AUTOSAR XML (schema 00047)
standard types defined: uint16, uint8
package /DemoApplication/ImplementationDataTypes
  impl type ComM_ModeType: compu {0=NO_COMMUNICATION, 1=SILENT_COMMUNICATION, 2=FULL_COMMUNICATION}, implementation-data-type=uint8
package /DemoApplication/PortInterfaces
  compu method DefaultBooleanCompuMethod: 0=false, 1=true
  sender receiver interface IfAdcVoltage
    data ArgData: type=uint16
  client server interface If_DiscreteValueOutput
    operation SetDiscreteValue
      arg value: type=uint32, direction=IN
  unit NoUnit
  client server interface NvMService0: is-service=true
    operation ReadBlock: fire-and-forget=false
      arg ReadArg: type=uint8, direction=IN, server-argument-impl-policy=USE-ARGUMENT-TYPE
    operation WriteBlock: fire-and-forget=false
      arg WriteArg: type=uint8, direction=IN, server-argument-impl-policy=USE-ARGUMENT-TYPE
    error E_NOT_OK: error-code=1
    error E_OK: error-code=0
package /DemoApplication/SwComponentTypes
  sw addr method LEDCODE: memory-allocation-keyword-policy=ADDR-METHOD-SHORT-NAME
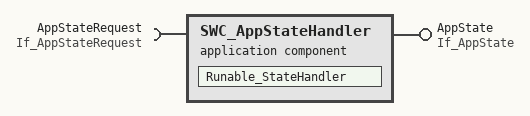
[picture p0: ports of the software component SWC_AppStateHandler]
  application sw component type SWC_AppStateHandler
    provide port AppState: mode-switch-sender-com-spec{mode-group=AppStateMode, queue-length=2}, provided-interface=If_AppState
    require port AppStateRequest: nonqueued-receiver-com-spec{data-element=If_AppStateRequestMode, init-value=EB_INTGR_APP_STARTUP}, required-interface=If_AppStateRequest
    behavior IB_SWC_AppStateHandler: data-type-mapping=AppModeMapping, handle-termination-and-restart=NO-SUPPORT
      data received event AppState: start-on-event=Runable_StateHandler, data=AppStateRequest.If_AppStateRequestMode
      runnable Runable_StateHandler: mode-access-point=AppState.AppStateMode, symbol=App_StateHandler
        data-read-access:
          access DRA_requestMode: accessed-variable=AppStateRequest.If_AppStateRequestMode
        mode switch point MSP_Mode: mode-group=AppState.AppStateMode
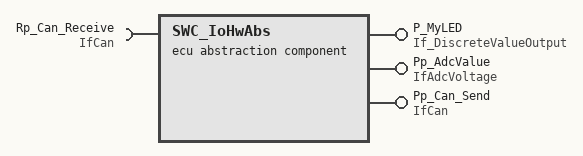
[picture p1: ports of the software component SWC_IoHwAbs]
  ecu abstraction sw component type SWC_IoHwAbs
    provide port P_MyLED: server-com-spec{operation=SetDiscreteValue, queue-length=1}, provided-interface=If_DiscreteValueOutput
    provide port Pp_AdcValue: nonqueued-sender-com-spec{data-element=ArgData, handle-out-of-range=DEFAULT, uses-end-to-end-protection=0, init-value=0}, provided-interface=IfAdcVoltage
    provide port Pp_Can_Send: nonqueued-sender-com-spec{data-element=Can, data-update-period=1.0, handle-out-of-range=DEFAULT, transmission-acknowledge=timeout=0.0, uses-end-to-end-protection=0}, provided-interface=IfCan
    require port Rp_Can_Receive: nonqueued-receiver-com-spec{data-element=Can, init-value=0}, required-interface=IfCan
    behavior IB_SWC_IoHwAbs: handle-termination-and-restart=NO-SUPPORT, port-api-option{enable-take-address=false, indirect-api=false, port-defined-argument-value{value=0, value-type=uint32}, port=P_MyLED}
      4 x timing event, all with offset=0.0:
        Adc_timingEvent: start-on-event=Adc_ReadValue, period=0.2
        LedTiming: start-on-event=LedControl_IO, period=0.2
        Recrive_Cyclic: start-on-event=Can_Receive, period=1.0
        Send_Cyclic: start-on-event=Can_Send, period=1.0
      operation invoked event SetDiscreteValueOperationInvoked: start-on-event=SetDiscreteValue, operation=P_MyLED.SetDiscreteValue
      5 x runnable:
        Adc_ReadValue
          data-send-points:
            access dsp_ArgData: accessed-variable=Pp_AdcValue.ArgData
        Can_Receive
          data-receive-point-by-values:
            access drpval_Can: accessed-variable=Rp_Can_Receive.Can
        Can_Send
          data-send-points:
            access dsp_Can: accessed-variable=Pp_Can_Send.Can
        LedControl_IO: can-be-invoked-concurrently=true
        SetDiscreteValue: can-be-invoked-concurrently=true, symbol=SWC_IoHwAbs_SetDiscreteValue
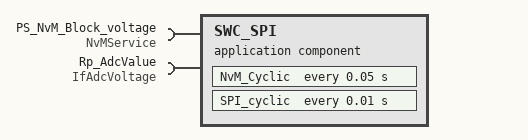
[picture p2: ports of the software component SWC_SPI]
  application sw component type SWC_SPI
    require port PS_NvM_Block_voltage: required-interface=NvMService
    require port Rp_AdcValue: nonqueued-receiver-com-spec=data-element=ArgData, required-interface=IfAdcVoltage
    behavior SWC_SPI_IB_0: handle-termination-and-restart=NO-SUPPORT
      timing event NvM_Cyclic_Event: start-on-event=NvM_Cyclic, offset=0.0, period=0.05
      timing event SPI_cyclic_Tim: start-on-event=SPI_cyclic, offset=0.0, period=0.01
      init event SPI_int
      runnable NvM_Cyclic
        data-receive-point-by-arguments:
          access drparg_ArgData: accessed-variable=Rp_AdcValue.ArgData
        sync call scp_ReadBlock: operation=PS_NvM_Block_voltage.ReadBlock, timeout=0.0
        sync call scp_WriteBlock: operation=PS_NvM_Block_voltage.WriteBlock, timeout=0.0
      runnable SPI_cyclic
      swc service dependency NvmBlockNeedvoltage: assigned-datas=role-based-data-assignment=ramBlock, assigned-ports=role-based-port-assignment={port-prototype=PS_NvM_Block_voltage, role=NvMService}
        service-needs:
          nv block needs NvBlockVoltage: n-data-sets=1, reliability=NO-PROTECTION, resistant-to-changed-sw=false, restore-at-start=true, store-at-shutdown=true, write-only-once=false, writing-frequency=0, writing-priority=MEDIUM
  composition sw component type TopLevelComposition
    component SWC_AppStateHandler: type=SWC_AppStateHandler
    component SWC_IoHwAbs: type=SWC_IoHwAbs
    component SWC_SPI: type=SWC_SPI
  base type Uint8_user: category=FIXED_LENGTH, base-type-size=8, base-type-encoding=NONE
package /DemoApplication/SwcImplementations
  sw addr method CODE: memory-allocation-keyword-policy=ADDR-METHOD-SHORT-NAME
  swc implementation Impl_SWC_AppStateHandler: programming-language=C, sw-version=1.0.0, vendor-id=1, behavior=IB_SWC_AppStateHandler
    code-descriptors:
      code SRC: artifact-descriptors=autosar-engineering-object={short-label=EngObject, category=SWSRC}
    resource consumption Resources
      memory section RTE_START_SEC_APPL_CODE: sw-addrmethod=CODE, symbol=CODE
  swc implementation Impl_SWC_IoHwAbs: programming-language=C, sw-version=1.0.0, vendor-id=0, behavior=IB_SWC_IoHwAbs
    code-descriptors:
      code SRC: artifact-descriptors=autosar-engineering-object={short-label=EngObject, category=SWSRC}
    resource consumption ResourceConsumption
      memory section RTE_START_SEC_APPL_CODE: size=0, sw-addrmethod=CODE, symbol=CODE
      memory section RTE_START_SEC_VAR_UNSPECIFIED: size=0, sw-addrmethod=VAR, symbol=VAR
  swc implementation Impl_SWC_SPI: programming-language=C, sw-version=1.0.0, vendor-id=0, behavior=SWC_SPI_IB_0
    code-descriptors:
      code SRC: artifact-descriptors=autosar-engineering-object={short-label=EngObject, category=SWSRC}
    resource consumption ResourceConsumption
      memory section RTE_START_SEC_APPL_CODE: size=0, sw-addrmethod=CODE, symbol=CODE
  sw addr method VAR: memory-allocation-keyword-policy=ADDR-METHOD-SHORT-NAME
